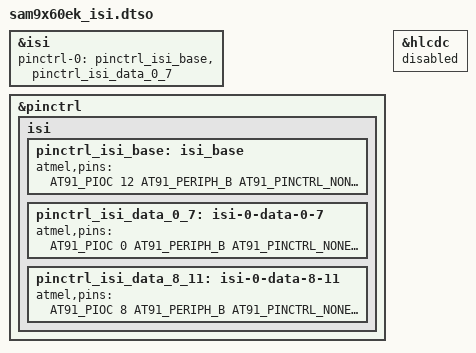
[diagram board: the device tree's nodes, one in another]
// SPDX-License-Identifier: (GPL-2.0+ OR MIT)
/*
 * sam9x60ek_isi.dtso - Device Tree file for SAM9X60EK board
 * overlay blob for Image Sensor Interface.
 *
 * Copyright (C) 2019 Microchip Technology Inc. and its subsidiaries
 *
 * Author: Tudor Ambarus <tudor.ambarus@microchip.com>
 */
/dts-v1/;
/plugin/;

#include <dt-bindings/pinctrl/at91.h>

&isi {
	pinctrl-names = "default";
	pinctrl-0 = <&pinctrl_isi_base &pinctrl_isi_data_0_7>;
	status = "okay";
};

&pinctrl {
	isi {
		pinctrl_isi_base: isi_base {
			atmel,pins =
				<AT91_PIOC 12 AT91_PERIPH_B AT91_PINCTRL_NONE   /* ISI_PCK, conflicts with LCDDAT12 */
				 AT91_PIOC 13 AT91_PERIPH_B AT91_PINCTRL_NONE   /* ISI_VSYNC, conflicts with LCDDAT13 */
				 AT91_PIOC 14 AT91_PERIPH_B AT91_PINCTRL_NONE>; /* ISI_HSYNC, conflicts with LCDDAT14 */
		};

		pinctrl_isi_data_0_7: isi-0-data-0-7 {
			atmel,pins =
				<AT91_PIOC 0 AT91_PERIPH_B AT91_PINCTRL_NONE	/* ISI_D0, conflicts with LCDDAT0 */
				 AT91_PIOC 1 AT91_PERIPH_B AT91_PINCTRL_NONE	/* ISI_D1, conflicts with LCDDAT1 */
				 AT91_PIOC 2 AT91_PERIPH_B AT91_PINCTRL_NONE	/* ISI_D2, conflicts with LCDDAT2 */
				 AT91_PIOC 3 AT91_PERIPH_B AT91_PINCTRL_NONE	/* ISI_D3, conflicts with LCDDAT3 */
				 AT91_PIOC 4 AT91_PERIPH_B AT91_PINCTRL_NONE	/* ISI_D4, conflicts with LCDDAT4 */
				 AT91_PIOC 5 AT91_PERIPH_B AT91_PINCTRL_NONE	/* ISI_D5, conflicts with LCDDAT5 */
				 AT91_PIOC 6 AT91_PERIPH_B AT91_PINCTRL_NONE	/* ISI_D6, conflicts with LCDDAT6 */
				 AT91_PIOC 7 AT91_PERIPH_B AT91_PINCTRL_NONE>;	/* ISI_D7, conflicts with LCDDAT7 */
		};

		pinctrl_isi_data_8_11: isi-0-data-8-11 {
			atmel,pins =
				<AT91_PIOC 8 AT91_PERIPH_B AT91_PINCTRL_NONE	/* ISI_D8, conflicts with LCDDAT8 */
				 AT91_PIOC 9 AT91_PERIPH_B AT91_PINCTRL_NONE	/* ISI_D9, conflicts with LCDDAT9 */
				 AT91_PIOC 10 AT91_PERIPH_B AT91_PINCTRL_NONE	/* ISI_D10, conflicts with LCDDAT10 */
				 AT91_PIOC 11 AT91_PERIPH_B AT91_PINCTRL_NONE>;	/* ISI_D11, conflicts with LCDDAT11 */
		};
	};
};

&hlcdc {
	status = "disabled";	/* conflict with ISI */
};

